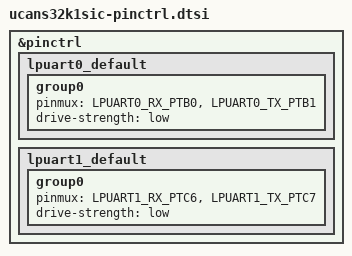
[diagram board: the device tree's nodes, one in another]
/*
 * Copyright 2023 NXP
 *
 * SPDX-License-Identifier: Apache-2.0
 */

#include <nxp/s32/S32K146_LQFP64-pinctrl.h>

&pinctrl {
	lpuart0_default: lpuart0_default {
		group0 {
			pinmux = <LPUART0_RX_PTB0>, <LPUART0_TX_PTB1>;
			drive-strength = "low";
		};
	};

	lpuart1_default: lpuart1_default {
		group0 {
			pinmux = <LPUART1_RX_PTC6>, <LPUART1_TX_PTC7>;
			drive-strength = "low";
		};
	};
};
